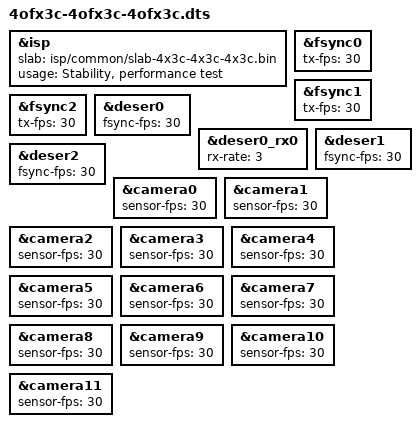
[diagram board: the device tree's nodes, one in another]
/dts-v1/;
/plugin/;

#include "../common/isp-csi-map.dtsi"
#include "base-isp.dtsi"
#include "base-csi-deser-camera.dtsi"
#include "base-desers-3max96724.dtsi"

&isp {
	slab = "isp/common/slab-4x3c-4x3c-4x3c.bin";
	usage = "Stability, performance test";
};
&fsync0 {
	tx-fps = <30>;
};
&fsync1 {
	tx-fps = <30>;
};
&fsync2 {
	tx-fps = <30>;
};
&deser0 {
	fsync-fps = <30>;
};
&deser0_rx0 {
	rx-rate = <3>;
};
&deser1 {
	fsync-fps = <30>;
};
&deser2 {
	fsync-fps = <30>;
};
&camera0 {
	#include "../cameras/ox03c_raw14_of_1920x1080.dtsi"
	sensor-fps = <30>;
	status = "okay";
};
&camera1 {
	#include "../cameras/ox03c_raw14_of_1920x1080.dtsi"
	sensor-fps = <30>;
	status = "okay";
};
&camera2 {
	#include "../cameras/ox03c_raw14_of_1920x1080.dtsi"
	sensor-fps = <30>;
	status = "okay";
};
&camera3 {
	#include "../cameras/ox03c_raw14_of_1920x1080.dtsi"
	sensor-fps = <30>;
	status = "okay";
};
&camera4 {
	#include "../cameras/ox03c_raw14_of_1920x1080.dtsi"
	sensor-fps = <30>;
	status = "okay";
};
&camera5 {
	#include "../cameras/ox03c_raw14_of_1920x1080.dtsi"
	sensor-fps = <30>;
	status = "okay";
};
&camera6 {
	#include "../cameras/ox03c_raw14_of_1920x1080.dtsi"
	sensor-fps = <30>;
	status = "okay";
};
&camera7 {
	#include "../cameras/ox03c_raw14_of_1920x1080.dtsi"
	sensor-fps = <30>;
	status = "okay";
};
&camera8 {
	#include "../cameras/ox03c_raw14_of_1920x1080.dtsi"
	sensor-fps = <30>;
	status = "okay";
};
&camera9 {
	#include "../cameras/ox03c_raw14_of_1920x1080.dtsi"
	sensor-fps = <30>;
	status = "okay";
};
&camera10 {
	#include "../cameras/ox03c_raw14_of_1920x1080.dtsi"
	sensor-fps = <30>;
	status = "okay";
};
&camera11 {
	#include "../cameras/ox03c_raw14_of_1920x1080.dtsi"
	sensor-fps = <30>;
	status = "okay";
};
